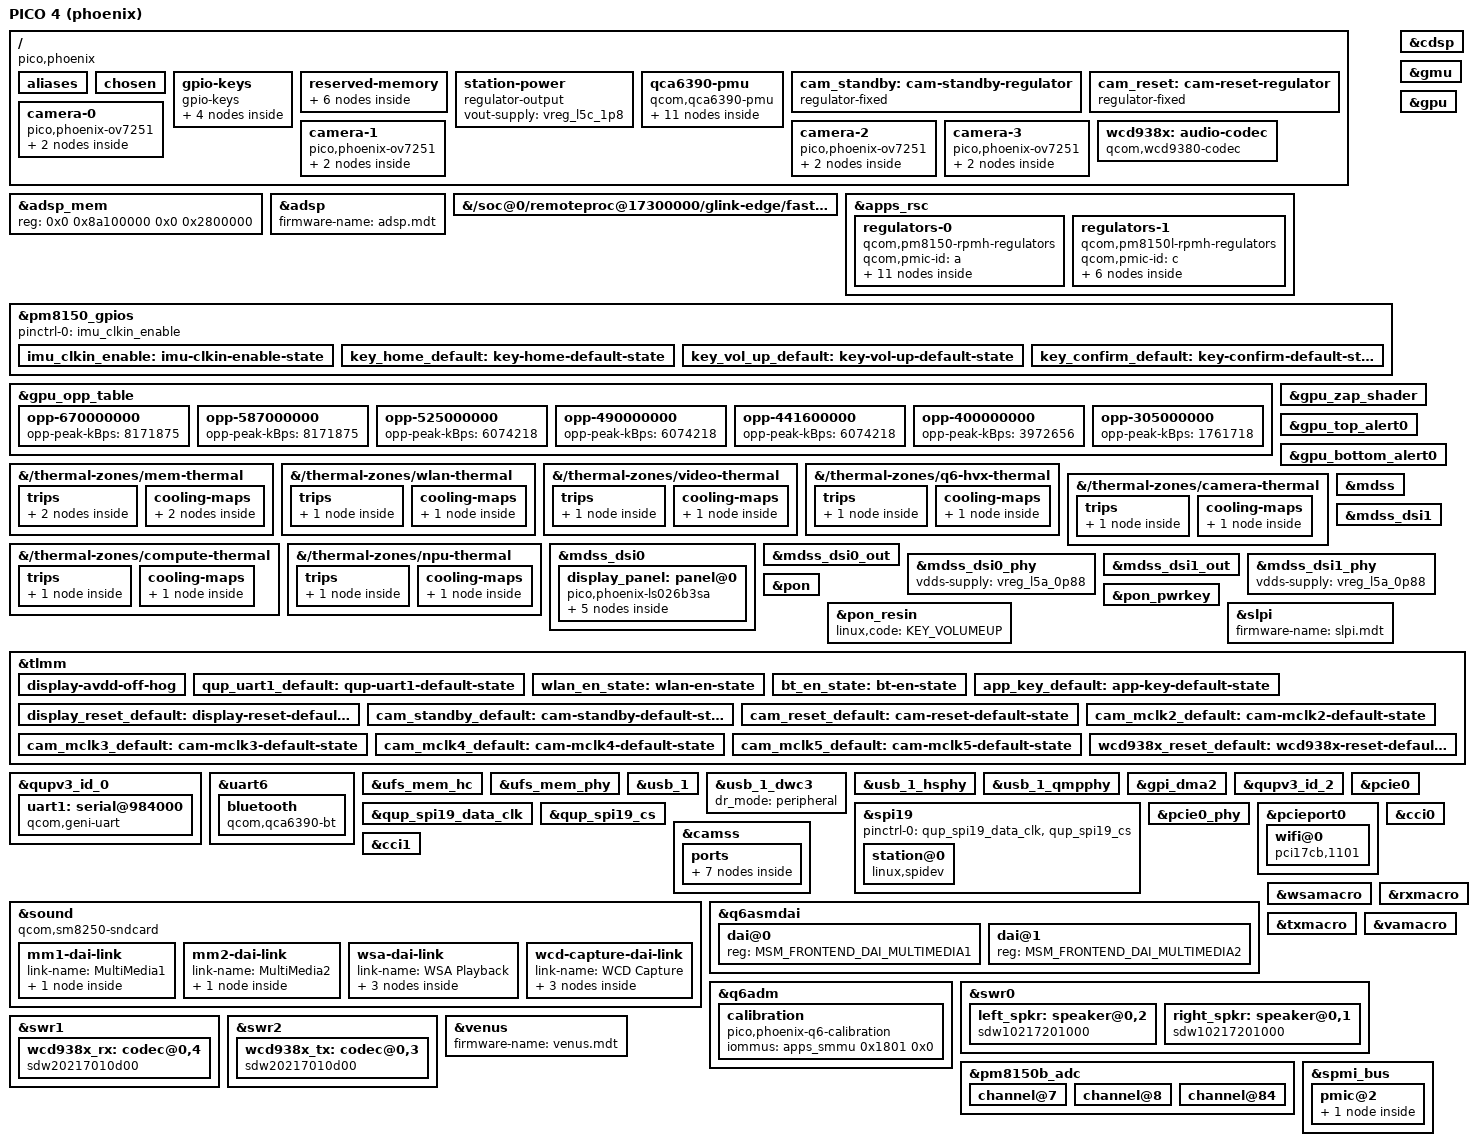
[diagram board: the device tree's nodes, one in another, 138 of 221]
// SPDX-License-Identifier: BSD-3-Clause
/*
 * PICO 4 (phoenix) on a mainline-based kernel: the prototype of a Steam Frame-level kernel
 * (docs/kernel-feasibility.md). Phase 0: storage, the USB gadget, reboot modes and a RAM
 * console. Phase 1: the two panels on the bonded DSI links, and the GPU.
 *
 * The board is Qualcomm's "kona MTP" design (the stock tree is kona v2.1 with the MTP overlay,
 * board-id 0x10008). Supplies, memory carve-outs and GPIOs follow the headset's own stock tree,
 * read from the running stock kernel, not mainline's MTP where the two differ.
 */

/dts-v1/;

#include <dt-bindings/arm/qcom,ids.h>
#include <dt-bindings/firmware/qcom,scm.h>
#include <dt-bindings/input/input.h>
#include <dt-bindings/regulator/qcom,rpmh-regulator.h>
#include "sm8250.dtsi"
#include "pm8150.dtsi"
/* PM8150B: the charger and fuel gauge's PMIC (its temperature alarm, ADC and GPIOs here). */
#include "pm8150b.dtsi"

/ {
	model = "PICO 4 (phoenix)";
	compatible = "pico,phoenix", "qcom,sm8250";
	chassis-type = "embedded";

	/*
	 * The ABL's board overlay replaces the root's compatible and model with downstream ones
	 * ("qcom,kona-mtp"); the kernel puts these back (patches/0003), so that drivers matching
	 * on the machine find "qcom,sm8250".
	 */
	pico4,compatible = "pico,phoenix", "qcom,sm8250";
	pico4,model = "PICO 4 (phoenix)";

	/*
	 * The ABL picks the base tree by SoC (SM8250 v2.1); the stock base trees carry board-id 0,
	 * the board comes from the dtbo overlay.
	 */
	qcom,msm-id = <QCOM_ID_SM8250 0x20001>;
	qcom,board-id = <0 0>;

	/* The GD32 MCU's UART keeps its stock name, which the fan, IPD and lens tools open. */
	aliases {
		serial1 = &uart1;
		/* The station's bus as bus 0: its spidev is /dev/spidev0.0, as on the stock kernel. */
		spi0 = &spi19;
	};

	chosen {
		#address-cells = <2>;
		#size-cells = <2>;
		ranges;
	};

	/*
	 * The stock tree's GPIO keys, with its labels and codes (its "volume_up" sends
	 * KEY_VOLUMEDOWN, as on PICO OS).
	 */
	gpio-keys {
		compatible = "gpio-keys";
		label = "gpio-keys";
		pinctrl-names = "default";
		pinctrl-0 = <&key_vol_up_default>, <&key_home_default>, <&key_confirm_default>,
			    <&app_key_default>;

		key-volume-up {
			label = "volume_up";
			gpios = <&pm8150_gpios 6 GPIO_ACTIVE_LOW>;
			linux,input-type = <EV_KEY>;
			linux,code = <KEY_VOLUMEDOWN>;
			wakeup-source;
			debounce-interval = <15>;
			linux,can-disable;
		};

		key-confirm {
			label = "confirm_key";
			gpios = <&pm8150_gpios 7 GPIO_ACTIVE_LOW>;
			linux,input-type = <EV_KEY>;
			linux,code = <KEY_ENTER>;
			wakeup-source;
			debounce-interval = <15>;
			linux,can-disable;
		};

		key-home {
			label = "home";
			gpios = <&pm8150_gpios 1 GPIO_ACTIVE_LOW>;
			linux,input-type = <EV_KEY>;
			linux,code = <KEY_HOME>;
			wakeup-source;
			debounce-interval = <15>;
			linux,can-disable;
		};

		key-app {
			label = "app_key";
			gpios = <&tlmm 40 GPIO_ACTIVE_LOW>;
			linux,input-type = <EV_KEY>;
			linux,code = <KEY_BACK>;
			wakeup-source;
			debounce-interval = <15>;
			linux,can-disable;
		};
	};

	reserved-memory {
		/*
		 * A RAM console that survives a warm reboot, laid out exactly as the stock kernel's
		 * (ramoops_memreserve=2M: 1 MiB console, 1 MiB pmsg, no dump records, no ECC), so
		 * that what a failed boot printed is in /sys/fs/pstore of the installed system on
		 * the stock kernel. Directly above the ABL's ramdisk and device tree.
		 */
		ramoops@b0000000 {
			compatible = "ramoops";
			reg = <0x0 0xb0000000 0x0 0x200000>;
			console-size = <0x100000>;
			pmsg-size = <0x100000>;
			record-size = <0>;
			no-map;
		};

		/* The stock tree's spss region (mainline's sits inside the stock adsp region). */
		spss_region: memory@8c900000 {
			reg = <0x0 0x8c900000 0x0 0x100000>;
			no-map;
		};

		/* Kept reserved like mainline's cdsp_secure_heap, moved behind the stock spss region. */
		cdsp_secure_region: memory@8ca00000 {
			reg = <0x0 0x8ca00000 0x0 0x4600000>;
			no-map;
		};

		/* The ABL's boot splash, still scanned out when the kernel starts. */
		cont_splash_region: memory@9c000000 {
			reg = <0x0 0x9c000000 0x0 0x3400000>;
			no-map;
		};

		dfps_data_region: memory@9f400000 {
			reg = <0x0 0x9f400000 0x0 0x40000>;
			no-map;
		};

		/*
		 * The stock remote heap for the audio DSP's static process (its adsp_region: 12 MiB
		 * of CMA below 4 GiB, 4 MiB aligned), which FastRPC hands to the DSP.
		 */
		adsp_rpc_heap: adsp-rpc-heap {
			compatible = "shared-dma-pool";
			alloc-ranges = <0x0 0x0 0x0 0xffffffff>;
			reusable;
			alignment = <0x0 0x400000>;
			size = <0x0 0xc00000>;
		};
	};
};

/delete-node/ &spss_mem;
/delete-node/ &cdsp_secure_heap;

/* The stock tree's adsp carve-out is 40 MiB (mainline: 29 MiB). */
&adsp_mem {
	reg = <0x0 0x8a100000 0x0 0x2800000>;
};

/*
 * The three DSPs with PICO's own signed images from the headset's modem partition, which the
 * userspace installs in /usr/lib/firmware: the audio DSP, the sensor DSP (head IMU, controllers
 * through ble_mcu, proximity) and the compute DSP (PICO OS's tracker). Their carve-outs are the
 * stock tree's. Without the files at probe (stage 1), each stays offline until it is started.
 */
&adsp {
	firmware-name = "adsp.mdt";
	status = "okay";
};

/*
 * The audio DSP's FastRPC channel: PICO OS's audio process (audiopd, which the userspace starts)
 * gets the stock remote heap, given to the DSP's VMs as the stock tree gives it
 * (qcom,adsp-remoteheap-vmid).
 */
&{/soc@0/remoteproc@17300000/glink-edge/fastrpc} {
	memory-region = <&adsp_rpc_heap>;
	qcom,vmids = <QCOM_SCM_VMID_LPASS QCOM_SCM_VMID_ADSP_HEAP>;
};

&apps_rsc {
	regulators-0 {
		compatible = "qcom,pm8150-rpmh-regulators";
		qcom,pmic-id = "a";

		/* Only the supplies the enabled blocks use; the voltages are the stock tree's. */
		vreg_s4a_1p8: smps4 {
			regulator-name = "vreg_s4a_1p8";
			regulator-min-microvolt = <1800000>;
			regulator-max-microvolt = <1920000>;
		};

		/*
		 * The QCA6390's 1.9 V and 0.95 V rails. The stock WLAN and Bluetooth drivers ask RPMh
		 * for 1.9 V and 0.95 V, which mainline can only vote in the regulators' steps: the next
		 * ones up, as RPMh rounds.
		 */
		vreg_s5a_1p9: smps5 {
			regulator-name = "vreg_s5a_1p9";
			regulator-min-microvolt = <1904000>;
			regulator-max-microvolt = <1904000>;
			regulator-initial-mode = <RPMH_REGULATOR_MODE_HPM>;
		};

		vreg_s6a_0p95: smps6 {
			regulator-name = "vreg_s6a_0p95";
			regulator-min-microvolt = <952000>;
			regulator-max-microvolt = <952000>;
			regulator-initial-mode = <RPMH_REGULATOR_MODE_HPM>;
		};

		vreg_l2a_3p1: ldo2 {
			regulator-name = "vreg_l2a_3p1";
			regulator-min-microvolt = <3072000>;
			regulator-max-microvolt = <3072000>;
			regulator-initial-mode = <RPMH_REGULATOR_MODE_HPM>;
		};

		vreg_l5a_0p88: ldo5 {
			regulator-name = "vreg_l5a_0p88";
			regulator-min-microvolt = <880000>;
			regulator-max-microvolt = <880000>;
			regulator-initial-mode = <RPMH_REGULATOR_MODE_HPM>;
		};

		vreg_l6a_1p2: ldo6 {
			regulator-name = "vreg_l6a_1p2";
			regulator-min-microvolt = <1200000>;
			regulator-max-microvolt = <1200000>;
			regulator-initial-mode = <RPMH_REGULATOR_MODE_HPM>;
		};

		/*
		 * The panels' VDDIO: the stock tree allows 1.8-1.9 V and its panel driver asks RPMh
		 * for 1.9 V. Mainline needs an exact LDO step (8 mV from 1.504 V): 1.896 V is the
		 * closest within the stock range. Enabling it at 1.904 V, above the range, stalled
		 * CPU 0.
		 */
		vreg_l7a_1p9: ldo7 {
			regulator-name = "vreg_l7a_1p9";
			regulator-min-microvolt = <1896000>;
			regulator-max-microvolt = <1896000>;
			regulator-initial-mode = <RPMH_REGULATOR_MODE_HPM>;
		};

		vreg_l9a_1p2: ldo9 {
			regulator-name = "vreg_l9a_1p2";
			regulator-min-microvolt = <1200000>;
			regulator-max-microvolt = <1200000>;
			regulator-initial-mode = <RPMH_REGULATOR_MODE_HPM>;
		};

		vreg_l12a_1p8: ldo12 {
			regulator-name = "vreg_l12a_1p8";
			regulator-min-microvolt = <1800000>;
			regulator-max-microvolt = <1800000>;
			regulator-initial-mode = <RPMH_REGULATOR_MODE_HPM>;
		};

		/* UFS 3.1 VCC: the stock driver asks for 2.504-2.95 V. */
		vreg_l17a_2p5: ldo17 {
			regulator-name = "vreg_l17a_2p5";
			regulator-min-microvolt = <2504000>;
			regulator-max-microvolt = <2952000>;
			regulator-initial-mode = <RPMH_REGULATOR_MODE_HPM>;
		};

		vreg_l18a_0p9: ldo18 {
			regulator-name = "vreg_l18a_0p9";
			regulator-min-microvolt = <912000>;
			regulator-max-microvolt = <920000>;
			regulator-initial-mode = <RPMH_REGULATOR_MODE_HPM>;
		};
	};

	regulators-1 {
		compatible = "qcom,pm8150l-rpmh-regulators";
		qcom,pmic-id = "c";

		/*
		 * The GD32 MCU's supply at the stock initial 3.0 V: the stock tree gives it to the
		 * MCU's UART, which keeps it on. The MCU drives the backlight, the fan and the
		 * lens motor, so it stays on here too.
		 */
		vreg_l10c_3p0: ldo10 {
			regulator-name = "vreg_l10c_3p0";
			regulator-min-microvolt = <3000000>;
			regulator-max-microvolt = <3000000>;
			regulator-initial-mode = <RPMH_REGULATOR_MODE_HPM>;
			regulator-always-on;
		};

		/*
		 * The head IMU's (TDK ICM-4x6xx on the sensor DSP) VDDIO and VDD at the stock voltages:
		 * the stock kernel's XR driver (qcom,xr-stdalonevwr-misc) holds both on.
		 */
		vreg_l8c_1p8: ldo8 {
			regulator-name = "vreg_l8c_1p8";
			regulator-min-microvolt = <1800000>;
			regulator-max-microvolt = <1800000>;
			regulator-initial-mode = <RPMH_REGULATOR_MODE_HPM>;
			regulator-always-on;
		};

		/* The QCA6390's 1.35 V rail (the stock drivers' 1.35 V, the next step up). */
		vreg_s8c_1p3: smps8 {
			regulator-name = "vreg_s8c_1p3";
			regulator-min-microvolt = <1352000>;
			regulator-max-microvolt = <1352000>;
			regulator-initial-mode = <RPMH_REGULATOR_MODE_HPM>;
		};

		vreg_l11c_3p0: ldo11 {
			regulator-name = "vreg_l11c_3p0";
			regulator-min-microvolt = <3008000>;
			regulator-max-microvolt = <3008000>;
			regulator-initial-mode = <RPMH_REGULATOR_MODE_HPM>;
			regulator-always-on;
		};

		/*
		 * PM8150L's BOB at the stock range: the stock tree's supply for the codec's
		 * microphone bias and a supply every camera sensor node names (cam_bob-supply).
		 */
		vreg_bob: bob {
			regulator-name = "vreg_bob";
			regulator-min-microvolt = <3008000>;
			regulator-max-microvolt = <3960000>;
			regulator-initial-mode = <RPMH_REGULATOR_MODE_AUTO>;
		};

		/*
		 * The controller station's supply at the stock initial 1.8 V: the stock tree gives it
		 * to the station's SPI bus (vdd-supply), whose vendor spidev switches it with a power
		 * ioctl. Here station-power hands that switch to userspace. On at boot: RPMh reports
		 * a regulator's state only once it has been set, and the switch needs to know it.
		 */
		vreg_l5c_1p8: ldo5 {
			regulator-name = "vreg_l5c_1p8";
			regulator-min-microvolt = <1800000>;
			regulator-max-microvolt = <1800000>;
			regulator-initial-mode = <RPMH_REGULATOR_MODE_HPM>;
			regulator-boot-on;
		};
	};
};

/*
 * The head IMU's CLKIN: PM8150's GPIO 3 in its first special function, the clock the IMU runs
 * from, as the stock XR driver sets it ("imu_clkin_enable").
 */
&pm8150_gpios {
	pinctrl-names = "default";
	pinctrl-0 = <&imu_clkin_enable>;

	imu_clkin_enable: imu-clkin-enable-state {
		pins = "gpio3";
		function = "func1";
		power-source = <0>;
		output-low;
		bias-disable;
		input-disable;
	};

	/* The keys' pins as the stock tree configures them. */
	key_home_default: key-home-default-state {
		pins = "gpio1";
		function = "normal";
		input-enable;
		bias-pull-up;
		power-source = <0>;
	};

	key_vol_up_default: key-vol-up-default-state {
		pins = "gpio6";
		function = "normal";
		input-enable;
		bias-pull-up;
		power-source = <1>;
	};

	key_confirm_default: key-confirm-default-state {
		pins = "gpio7";
		function = "normal";
		input-enable;
		bias-pull-up;
		power-source = <1>;
	};
};

/*
 * The stock loader holds a bus vote from the compute DSP to its memory NoC while it starts
 * (master 154 to slave 10070, the path mainline names qnm_npu to qns_cdsp_mem_noc); without
 * it, TrustZone refuses the start ("failed to authenticate image and release reset").
 */
&cdsp {
	firmware-name = "cdsp.mdt";
	interconnects = <&compute_noc MASTER_NPU 0 &compute_noc SLAVE_CDSP_MEM_NOC 0>;
	status = "okay";
};

&gmu {
	status = "okay";
};

/*
 * The GPU's own DDR vote, as the stock driver casts it: mainline's tree gives the A650 no
 * interconnect, so the DDR ran at what the CPUs asked for and the GPU's frames took up to a third
 * longer whenever they asked little. The stock tree's GPU bus table for LPDDR4X (the bootloader's
 * ddr_device_type 7) at each level's bus-freq-ddr7; KGSL's bus scaling between the levels'
 * bus-min and bus-max is not carried over: measured on the USB input with the battery full, the
 * stock levels' bus-min votes drew the same as these (within 1 %, the windows' spread 4 %), and the
 * top level's minimum is its vote. msm applies the OPP, and with it this vote, on every frequency
 * change.
 */
&gpu {
	interconnects = <&gem_noc MASTER_GRAPHICS_3D 0 &mc_virt SLAVE_EBI_CH0 0>;
	interconnect-names = "gfx-mem";
	status = "okay";
};

&gpu_opp_table {
	/*
	 * Not this headset's speed bin, but the OPP core looks for bandwidths in the first OPP only
	 * and without one there takes the table for one without them; the stock top level.
	 */
	opp-670000000 {
		opp-peak-kBps = <8171875>;	/* bus level 11 */
	};

	opp-587000000 {
		opp-peak-kBps = <8171875>;	/* bus level 11 */
	};

	opp-525000000 {
		opp-peak-kBps = <6074218>;	/* bus level 9 */
	};

	opp-490000000 {
		opp-peak-kBps = <6074218>;	/* bus level 9 */
	};

	opp-441600000 {
		opp-peak-kBps = <6074218>;	/* bus level 9 */
	};

	opp-400000000 {
		opp-peak-kBps = <3972656>;	/* bus level 7 */
	};

	opp-305000000 {
		opp-peak-kBps = <1761718>;	/* bus level 3 */
	};
};

/* PICO's signed zap shader, from the stock firmware (split .mdt with its segments). */
&gpu_zap_shader {
	firmware-name = "qcom/sm8250/pico/phoenix/a650_zap.mdt";
};

/*
 * The stock tree's kernel throttling, on mainline's zones: the GPU from 95 °C (gpuss-max-step;
 * mainline throttles at 85 °C, which a VR session reaches), the big and prime cores from a DDR
 * at 95 °C (pop-mem-step), and the GPU held at its second-lowest level, 400 MHz, from 100 °C at
 * the WLAN, video, DDR, DSP, camera, compute and NPU sensors (their -step zones; the stock tree
 * also caps the CDSP, the modem and the NPU there, which have no cooling devices here). The
 * CPUs keep mainline's frequency trips at 90 and 95 °C: the stock kernel only isolates cores at
 * 110 °C and leaves the rest to the CPUs' limits hardware, and 90 °C is this project's limit.
 */
&gpu_top_alert0 {
	temperature = <95000>;
	hysteresis = <0>;
};

&gpu_bottom_alert0 {
	temperature = <95000>;
	hysteresis = <0>;
};

&{/thermal-zones/mem-thermal} {
	trips {
		mem_pop: trip-pop {
			temperature = <95000>;
			hysteresis = <0>;
			type = "passive";
		};

		mem_step: trip-step {
			temperature = <100000>;
			hysteresis = <5000>;
			type = "passive";
		};
	};

	cooling-maps {
		map-pop {
			trip = <&mem_pop>;
			cooling-device = <&cpu4 THERMAL_NO_LIMIT THERMAL_NO_LIMIT>,
					 <&cpu7 THERMAL_NO_LIMIT THERMAL_NO_LIMIT>;
		};

		map-step {
			trip = <&mem_step>;
			cooling-device = <&gpu 4 4>;
		};
	};
};

&{/thermal-zones/wlan-thermal} {
	trips {
		wlan_step: trip-step {
			temperature = <100000>;
			hysteresis = <5000>;
			type = "passive";
		};
	};

	cooling-maps {
		map-step {
			trip = <&wlan_step>;
			cooling-device = <&gpu 4 4>;
		};
	};
};

&{/thermal-zones/video-thermal} {
	trips {
		video_step: trip-step {
			temperature = <100000>;
			hysteresis = <5000>;
			type = "passive";
		};
	};

	cooling-maps {
		map-step {
			trip = <&video_step>;
			cooling-device = <&gpu 4 4>;
		};
	};
};

&{/thermal-zones/q6-hvx-thermal} {
	trips {
		q6_hvx_step: trip-step {
			temperature = <100000>;
			hysteresis = <5000>;
			type = "passive";
		};
	};

	cooling-maps {
		map-step {
			trip = <&q6_hvx_step>;
			cooling-device = <&gpu 4 4>;
		};
	};
};

&{/thermal-zones/camera-thermal} {
	trips {
		camera_step: trip-step {
			temperature = <100000>;
			hysteresis = <5000>;
			type = "passive";
		};
	};

	cooling-maps {
		map-step {
			trip = <&camera_step>;
			cooling-device = <&gpu 4 4>;
		};
	};
};

&{/thermal-zones/compute-thermal} {
	trips {
		compute_step: trip-step {
			temperature = <100000>;
			hysteresis = <5000>;
			type = "passive";
		};
	};

	cooling-maps {
		map-step {
			trip = <&compute_step>;
			cooling-device = <&gpu 4 4>;
		};
	};
};

&{/thermal-zones/npu-thermal} {
	trips {
		npu_step: trip-step {
			temperature = <100000>;
			hysteresis = <5000>;
			type = "passive";
		};
	};

	cooling-maps {
		map-step {
			trip = <&npu_step>;
			cooling-device = <&gpu 4 4>;
		};
	};
};

&mdss {
	status = "okay";
};

/*
 * Two Sharp LS026B3SA panels, one per DSI link, as one bonded output: the first link is the
 * master, and both run from its PLL (the stock display's dsi-ctrl-num <0 1>).
 */
&mdss_dsi0 {
	vdda-supply = <&vreg_l9a_1p2>;
	qcom,dual-dsi-mode;
	qcom,master-dsi;
	status = "okay";

	display_panel: panel@0 {
		compatible = "pico,phoenix-ls026b3sa";
		reg = <0>;

		reset-gpios = <&tlmm 75 GPIO_ACTIVE_LOW>;
		vio-gpios = <&tlmm 133 GPIO_ACTIVE_HIGH>;
		backlight-gpios = <&tlmm 29 GPIO_ACTIVE_HIGH>;
		pinctrl-0 = <&display_reset_default>;
		pinctrl-names = "default";

		vddio-supply = <&vreg_l7a_1p9>;

		ports {
			#address-cells = <1>;
			#size-cells = <0>;

			port@0 {
				reg = <0>;
				panel_in0: endpoint {
					remote-endpoint = <&mdss_dsi0_out>;
				};
			};

			port@1 {
				reg = <1>;
				panel_in1: endpoint {
					remote-endpoint = <&mdss_dsi1_out>;
				};
			};
		};
	};
};

&mdss_dsi0_out {
	remote-endpoint = <&panel_in0>;
	data-lanes = <0 1 2 3>;
};

&mdss_dsi0_phy {
	vdds-supply = <&vreg_l5a_0p88>;
	status = "okay";
};

&mdss_dsi1 {
	vdda-supply = <&vreg_l9a_1p2>;
	qcom,dual-dsi-mode;
	assigned-clocks = <&dispcc DISP_CC_MDSS_BYTE1_CLK_SRC>, <&dispcc DISP_CC_MDSS_PCLK1_CLK_SRC>;
	assigned-clock-parents = <&mdss_dsi0_phy DSI_BYTE_PLL_CLK>, <&mdss_dsi0_phy DSI_PIXEL_PLL_CLK>;
	status = "okay";
};

&mdss_dsi1_out {
	remote-endpoint = <&panel_in1>;
	data-lanes = <0 1 2 3>;
};

&mdss_dsi1_phy {
	vdds-supply = <&vreg_l5a_0p88>;
	status = "okay";
};

&pon {
	mode-bootloader = <0x2>;
	mode-recovery = <0x1>;
};

/* The stock tree's power-on keys: KPDPWR is the power key, RESIN sends KEY_VOLUMEUP. */
&pon_pwrkey {
	status = "okay";
};

&pon_resin {
	linux,code = <KEY_VOLUMEUP>;
	status = "okay";
};

&slpi {
	firmware-name = "slpi.mdt";
	status = "okay";
};

&tlmm {
	/*
	 * Every GPIO the stock tree leaves unused (no pin configuration, no consumer) stays
	 * untouched, which covers the secure ones whose registers fault when read.
	 */
	gpio-reserved-ranges = <14 1>, <24 2>, <27 2>, <30 2>, <64 1>, <66 1>, <73 1>,
			       <88 3>, <112 2>, <120 5>, <146 34>;

	/*
	 * GPIO 71 switches a 5.5 V supply that the bootloader leaves on. The stock display does
	 * not use it, and the stock kernel switches it off as unused.
	 */
	display-avdd-off-hog {
		gpio-hog;
		gpios = <71 GPIO_ACTIVE_HIGH>;
		output-low;
		line-name = "display-avdd-off";
	};

	/* The GD32 MCU's UART, two wires as in the stock tree (its reset and boot lines stay unused). */
	qup_uart1_default: qup-uart1-default-state {
		pins = "gpio6", "gpio7";
		function = "qup1";
		drive-strength = <2>;
		bias-disable;
	};

	/* The QCA6390's enable lines as the stock tree configures them (cnss2's active state, btpower's). */
	wlan_en_state: wlan-en-state {
		pins = "gpio20";
		function = "gpio";
		drive-strength = <16>;
		bias-pull-up;
	};

	bt_en_state: bt-en-state {
		pins = "gpio21";
		function = "gpio";
		drive-strength = <2>;
		bias-pull-down;
	};

	/* The app key's pin as the stock tree configures it. */
	app_key_default: app-key-default-state {
		pins = "gpio40";
		function = "gpio";
		drive-strength = <6>;
		bias-pull-up;
	};

	/* The stock panel pins: the reset (75) and its neighbour 60, driven at 8 mA. */
	display_reset_default: display-reset-default-state {
		pins = "gpio75", "gpio60";
		function = "gpio";
		drive-strength = <8>;
		bias-disable;
	};
};

&qupv3_id_0 {
	status = "okay";

	/* QUP0's serial engine 1 as the stock tree uses it: the GD32 MCU at 115200 baud. */
	uart1: serial@984000 {
		compatible = "qcom,geni-uart";
		reg = <0 0x00984000 0 0x4000>;
		clock-names = "se";
		clocks = <&gcc GCC_QUPV3_WRAP0_S1_CLK>;
		pinctrl-names = "default";
		pinctrl-0 = <&qup_uart1_default>;
		interrupts = <GIC_SPI 602 IRQ_TYPE_LEVEL_HIGH>;
		power-domains = <&rpmhpd RPMHPD_CX>;
		operating-points-v2 = <&qup_opp_table>;
		interconnects = <&qup_virt MASTER_QUP_CORE_0 0 &qup_virt SLAVE_QUP_CORE_0 0>,
				<&gem_noc MASTER_AMPSS_M0 0 &config_noc SLAVE_QUP_0 0>;
		interconnect-names = "qup-core",
				     "qup-config";
	};
};

/*
 * Bluetooth: the QCA6390 on QUP0's serial engine 6, four wires, as the stock tree's
 * bt_qca6390 uses it.
 */
&uart6 {
	status = "okay";

	bluetooth {
		compatible = "qcom,qca6390-bt";

		vddrfacmn-supply = <&vreg_pmu_rfa_cmn>;
		vddaon-supply = <&vreg_pmu_aon_0p59>;
		vddbtcmx-supply = <&vreg_pmu_btcmx_0p85>;
		vddrfa0p8-supply = <&vreg_pmu_rfa_0p8>;
		vddrfa1p2-supply = <&vreg_pmu_rfa_1p2>;
		vddrfa1p7-supply = <&vreg_pmu_rfa_1p7>;
	};
};

&ufs_mem_hc {
	status = "okay";

	vcc-supply = <&vreg_l17a_2p5>;
	vcc-max-microamp = <800000>;
	vccq-supply = <&vreg_l6a_1p2>;
	vccq-max-microamp = <800000>;
	vccq2-supply = <&vreg_s4a_1p8>;
	vccq2-max-microamp = <800000>;
};

&ufs_mem_phy {
	status = "okay";

	vdda-phy-supply = <&vreg_l5a_0p88>;
	vdda-pll-supply = <&vreg_l9a_1p2>;
};

&usb_1 {
	status = "okay";
};

/* Device mode only: the headset is the PC's network adapter, as in stage 1 on the stock kernel. */
&usb_1_dwc3 {
	dr_mode = "peripheral";
};

&usb_1_hsphy {
	status = "okay";

	vdda-pll-supply = <&vreg_l5a_0p88>;
	vdda18-supply = <&vreg_l12a_1p8>;
	vdda33-supply = <&vreg_l2a_3p1>;
};

&usb_1_qmpphy {
	status = "okay";

	vdda-phy-supply = <&vreg_l9a_1p2>;
	vdda-pll-supply = <&vreg_l18a_0p9>;
};

/*
 * The controller station (Nordic nRF52832) on QUP2's serial engine 5 (SE19), as the stock board
 * overlay describes it: "picovr,nordic" at up to 6 MHz on GPIO 0-3 (6 mA), its interrupt line on
 * GPIO 11 (rfic-io2 and rfic-io3 on GPIO 4 and 8), and the camera frame sync on GPIO 84
 * (stationdev). Here it is a spidev, and userspace reads GPIO 11. Its power, L5C, is the
 * station-power output's state in sysfs, which takes the place of the vendor spidev's power
 * ioctl. The station's boot pin, GPIO 10, stays untouched: it selects the station's bootloader.
 */
&gpi_dma2 {
	status = "okay";
};

&qupv3_id_2 {
	status = "okay";
};

&qup_spi19_data_clk {
	drive-strength = <6>;
	bias-disable;
};

&qup_spi19_cs {
	drive-strength = <6>;
	bias-disable;
};

&spi19 {
	pinctrl-names = "default";
	pinctrl-0 = <&qup_spi19_data_clk>, <&qup_spi19_cs>;
	status = "okay";

	station@0 {
		compatible = "linux,spidev";
		reg = <0>;
		spi-max-frequency = <6000000>;
	};
};

/ {
	station-power {
		compatible = "regulator-output";
		vout-supply = <&vreg_l5c_1p8>;
	};
};

/*
 * Wi-Fi and Bluetooth: the QCA6390, wired as on Qualcomm's SM8250 reference boards. Its
 * power-management unit takes the stock tree's supplies (cnss2's vdd-wlan-* and btpower's
 * qca,bt-vdd-*: S6A for the 0.95 V rails, S8C for 1.35 V, S5A for 1.9 V, S4A for the I/O) and
 * enable lines (WLAN GPIO 20, Bluetooth GPIO 21); the WLAN function sits on PCIe 0 (the stock
 * tree's cnss_pci on pcie0_rp, the same reset, clock request and wake pins as mainline's).
 * The stock Bluetooth driver's antenna-sharing supply (L16A) and switch control (GPIO 124)
 * have no place in the mainline binding.
 */
/ {
	qca6390-pmu {
		compatible = "qcom,qca6390-pmu";

		pinctrl-names = "default";
		pinctrl-0 = <&bt_en_state>, <&wlan_en_state>;

		vddaon-supply = <&vreg_s6a_0p95>;
		vddpmu-supply = <&vreg_s6a_0p95>;
		vddrfa0p95-supply = <&vreg_s6a_0p95>;
		vddrfa1p3-supply = <&vreg_s8c_1p3>;
		vddrfa1p9-supply = <&vreg_s5a_1p9>;
		vddpcie1p3-supply = <&vreg_s8c_1p3>;
		vddpcie1p9-supply = <&vreg_s5a_1p9>;
		vddio-supply = <&vreg_s4a_1p8>;

		wlan-enable-gpios = <&tlmm 20 GPIO_ACTIVE_HIGH>;
		bt-enable-gpios = <&tlmm 21 GPIO_ACTIVE_HIGH>;

		regulators {
			vreg_pmu_rfa_cmn: ldo0 {
				regulator-name = "vreg_pmu_rfa_cmn";
			};

			vreg_pmu_aon_0p59: ldo1 {
				regulator-name = "vreg_pmu_aon_0p59";
			};

			vreg_pmu_wlcx_0p8: ldo2 {
				regulator-name = "vreg_pmu_wlcx_0p8";
			};

			vreg_pmu_wlmx_0p85: ldo3 {
				regulator-name = "vreg_pmu_wlmx_0p85";
			};

			vreg_pmu_btcmx_0p85: ldo4 {
				regulator-name = "vreg_pmu_btcmx_0p85";
			};

			vreg_pmu_rfa_0p8: ldo5 {
				regulator-name = "vreg_pmu_rfa_0p8";
			};

			vreg_pmu_rfa_1p2: ldo6 {
				regulator-name = "vreg_pmu_rfa_1p2";
			};

			vreg_pmu_rfa_1p7: ldo7 {
				regulator-name = "vreg_pmu_rfa_1p7";
			};

			vreg_pmu_pcie_0p9: ldo8 {
				regulator-name = "vreg_pmu_pcie_0p9";
			};

			vreg_pmu_pcie_1p8: ldo9 {
				regulator-name = "vreg_pmu_pcie_1p8";
			};
		};
	};
};

&pcie0 {
	status = "okay";
};

/* The stock tree's PCIe 0 PHY supplies, the UFS PHY's: L5A 0.88 V and L9A 1.2 V. */
&pcie0_phy {
	vdda-phy-supply = <&vreg_l5a_0p88>;
	vdda-pll-supply = <&vreg_l9a_1p2>;
	status = "okay";
};

&pcieport0 {
	wifi@0 {
		compatible = "pci17cb,1101";
		reg = <0x10000 0x0 0x0 0x0 0x0>;

		vddrfacmn-supply = <&vreg_pmu_rfa_cmn>;
		vddaon-supply = <&vreg_pmu_aon_0p59>;
		vddwlcx-supply = <&vreg_pmu_wlcx_0p8>;
		vddwlmx-supply = <&vreg_pmu_wlmx_0p85>;
		vddrfa0p8-supply = <&vreg_pmu_rfa_0p8>;
		vddrfa1p2-supply = <&vreg_pmu_rfa_1p2>;
		vddrfa1p7-supply = <&vreg_pmu_rfa_1p7>;
		vddpcie0p9-supply = <&vreg_pmu_pcie_0p9>;
		vddpcie1p8-supply = <&vreg_pmu_pcie_1p8>;
	};
};

/*
 * The four tracking cameras (OmniVision OV7251, 640x480 mono, one CSI-2 lane each), as the stock
 * board overlay wires them (its cam-sensor cells 0-3): MCLK 24 MHz from the camera clock
 * controller, one lane at 480 Mbit/s. Cells 1 and 2 share CSIPHY 3 in combo mode.
 * All four share their reset (GPIO 115) and standby (GPIO 42) lines; as fixed regulators the
 * two lines are switched once for all sensors. Power-up as the stock module's sequence: standby
 * and 18 ms, MCLK and 1 ms, reset and 18 ms.
 */
#include <dt-bindings/clock/qcom,camcc-sm8250.h>

/ {
	cam_standby: cam-standby-regulator {
		compatible = "regulator-fixed";
		regulator-name = "cam_standby";
		gpio = <&tlmm 42 GPIO_ACTIVE_HIGH>;
		enable-active-high;
		startup-delay-us = <18000>;
		pinctrl-names = "default";
		pinctrl-0 = <&cam_standby_default>;
	};

	cam_reset: cam-reset-regulator {
		compatible = "regulator-fixed";
		regulator-name = "cam_reset";
		gpio = <&tlmm 115 GPIO_ACTIVE_HIGH>;
		enable-active-high;
		startup-delay-us = <18000>;
		pinctrl-names = "default";
		pinctrl-0 = <&cam_reset_default>;
	};
};

&tlmm {
	cam_standby_default: cam-standby-default-state {
		pins = "gpio42";
		function = "gpio";
		drive-strength = <2>;
		bias-disable;
	};

	cam_reset_default: cam-reset-default-state {
		pins = "gpio115";
		function = "gpio";
		drive-strength = <2>;
		bias-disable;
	};

	/* The MCLK pins at 16 mA, as the stock camera stack drives them while the sensors run. */
	cam_mclk2_default: cam-mclk2-default-state {
		pins = "gpio96";
		function = "cam_mclk";
		drive-strength = <16>;
		bias-disable;
	};

	cam_mclk3_default: cam-mclk3-default-state {
		pins = "gpio97";
		function = "cam_mclk";
		drive-strength = <16>;
		bias-disable;
	};

	cam_mclk4_default: cam-mclk4-default-state {
		pins = "gpio98";
		function = "cam_mclk";
		drive-strength = <16>;
		bias-disable;
	};

	cam_mclk5_default: cam-mclk5-default-state {
		pins = "gpio99";
		function = "cam_mclk";
		drive-strength = <16>;
		bias-disable;
	};
};

&camss {
	vdda-phy-supply = <&vreg_l5a_0p88>;
	vdda-pll-supply = <&vreg_l9a_1p2>;
	status = "okay";

	ports {
		port@3 {
			#address-cells = <1>;
			#size-cells = <0>;

			csiphy3_cam1_ep: endpoint@0 {
				reg = <0>;
				clock-lanes = <7>;
				data-lanes = <0>;
				remote-endpoint = <&cam1_ep>;
			};

			/* The second sensor on the PHY (combo mode): data lane 2, lane 3 its clock. */
			csiphy3_cam2_ep: endpoint@1 {
				reg = <1>;
				clock-lanes = <3>;
				data-lanes = <2>;
				remote-endpoint = <&cam2_ep>;
			};
		};

		port@4 {
			csiphy4_ep: endpoint {
				clock-lanes = <7>;
				data-lanes = <0>;
				remote-endpoint = <&cam3_ep>;
			};
		};

		port@5 {
			csiphy5_ep: endpoint {
				clock-lanes = <7>;
				data-lanes = <0>;
				remote-endpoint = <&cam0_ep>;
			};
		};
	};
};

/* The CCIs run at the stock 37.5 MHz, the clock their I2C timings are made for (the default is 19.2). */
&cci0 {
	assigned-clocks = <&camcc CAM_CC_CCI_0_CLK_SRC>;
	assigned-clock-rates = <37500000>;
	status = "okay";
};

&cci1 {
	assigned-clocks = <&camcc CAM_CC_CCI_1_CLK_SRC>;
	assigned-clock-rates = <37500000>;
	status = "okay";
};

/*
 * The four tracking cameras (OV7251), each on its stock MCLK and CSIPHY. Their control port belongs
 * to the controller radio, which configures them and triggers each frame: PICO's stock kernel never
 * talks to them either (it takes their probes without reading a chip ID and drops their register
 * writes), so they are no I2C clients. Each holds the camera clock controller's TITAN_TOP GDSC, its
 * stock cam_clk supply, without which its MCLK does not run.
 */
/ {
	camera-0 {
		/* left, stock address 0xE2 */
		compatible = "pico,phoenix-ov7251";
		pico,camera-slot = <0>;
		clocks = <&camcc CAM_CC_MCLK3_CLK>;
		clock-names = "xclk";
		power-domains = <&camcc TITAN_TOP_GDSC>;
		assigned-clocks = <&camcc CAM_CC_MCLK3_CLK>;
		assigned-clock-rates = <24000000>;
		pinctrl-names = "default";
		pinctrl-0 = <&cam_mclk3_default>;
		standby-supply = <&cam_standby>;
		reset-supply = <&cam_reset>;

		port {
			cam0_ep: endpoint {
				data-lanes = <1>;
				link-frequencies = /bits/ 64 <240000000>;
				remote-endpoint = <&csiphy5_ep>;
			};
		};
	};

	camera-1 {
		/* right, 0xE4 */
		compatible = "pico,phoenix-ov7251";
		pico,camera-slot = <1>;
		clocks = <&camcc CAM_CC_MCLK4_CLK>;
		clock-names = "xclk";
		power-domains = <&camcc TITAN_TOP_GDSC>;
		assigned-clocks = <&camcc CAM_CC_MCLK4_CLK>;
		assigned-clock-rates = <24000000>;
		pinctrl-names = "default";
		pinctrl-0 = <&cam_mclk4_default>;
		standby-supply = <&cam_standby>;
		reset-supply = <&cam_reset>;

		port {
			cam1_ep: endpoint {
				data-lanes = <1>;
				link-frequencies = /bits/ 64 <240000000>;
				remote-endpoint = <&csiphy3_cam1_ep>;
			};
		};
	};

	camera-2 {
		/* "slave", 0xE6 */
		compatible = "pico,phoenix-ov7251";
		pico,camera-slot = <2>;
		clocks = <&camcc CAM_CC_MCLK2_CLK>;
		clock-names = "xclk";
		power-domains = <&camcc TITAN_TOP_GDSC>;
		assigned-clocks = <&camcc CAM_CC_MCLK2_CLK>;
		assigned-clock-rates = <24000000>;
		pinctrl-names = "default";
		pinctrl-0 = <&cam_mclk2_default>;
		standby-supply = <&cam_standby>;
		reset-supply = <&cam_reset>;

		port {
			cam2_ep: endpoint {
				data-lanes = <1>;
				link-frequencies = /bits/ 64 <240000000>;
				remote-endpoint = <&csiphy3_cam2_ep>;
			};
		};
	};

	camera-3 {
		/* "master", 0xE8 */
		compatible = "pico,phoenix-ov7251";
		pico,camera-slot = <3>;
		clocks = <&camcc CAM_CC_MCLK5_CLK>;
		clock-names = "xclk";
		power-domains = <&camcc TITAN_TOP_GDSC>;
		assigned-clocks = <&camcc CAM_CC_MCLK5_CLK>;
		assigned-clock-rates = <24000000>;
		pinctrl-names = "default";
		pinctrl-0 = <&cam_mclk5_default>;
		standby-supply = <&cam_standby>;
		reset-supply = <&cam_reset>;

		port {
			cam3_ep: endpoint {
				data-lanes = <1>;
				link-frequencies = /bits/ 64 <240000000>;
				remote-endpoint = <&csiphy4_ep>;
			};
		};
	};
};


/* Cells 0 (left, 0xE2) and 1 (right, 0xE4) on CCI 1, master 0, in fast mode as well. */
/*
 * Audio, as the stock tree wires it (kona-mtp-snd-card): two WSA8810 amplifiers, one per speaker,
 * on the WSA macro's SoundWire, and the WCD9380 codec (RX and TX SoundWire) whose ADC1 carries
 * the analog microphone (PICO OS's amic1, on MIC BIAS1). The DSP side is the audio DSP's APR
 * services (q6afe, q6asm, q6adm) in sm8250.dtsi.
 */
#include <dt-bindings/sound/qcom,q6afe.h>
#include <dt-bindings/sound/qcom,q6asm.h>

/ {
	wcd938x: audio-codec {
		compatible = "qcom,wcd9380-codec";

		pinctrl-names = "default";
		pinctrl-0 = <&wcd938x_reset_default>;
		reset-gpios = <&tlmm 32 GPIO_ACTIVE_LOW>;

		/* The stock supplies: S4A for the codec, BOB for the microphone bias. */
		vdd-buck-supply = <&vreg_s4a_1p8>;
		vdd-rxtx-supply = <&vreg_s4a_1p8>;
		vdd-io-supply = <&vreg_s4a_1p8>;
		vdd-mic-bias-supply = <&vreg_bob>;

		/* The stock 2.7 V on every bias. */
		qcom,micbias1-microvolt = <2700000>;
		qcom,micbias2-microvolt = <2700000>;
		qcom,micbias3-microvolt = <2700000>;
		qcom,micbias4-microvolt = <2700000>;
		/* The stock headphone switch (msm-mbhc-hphl-swh = 0); no jack is fitted. */
		qcom,hphl-jack-type-normally-closed;

		qcom,rx-device = <&wcd938x_rx>;
		qcom,tx-device = <&wcd938x_tx>;

		#sound-dai-cells = <1>;
	};
};

&sound {
	compatible = "qcom,sm8250-sndcard";
	model = "PICO4";
	audio-routing =
		"SpkrLeft IN", "WSA_SPK1 OUT",
		"SpkrRight IN", "WSA_SPK2 OUT",
		"AMIC1", "MIC BIAS1",
		"TX SWR_ADC0", "ADC1_OUTPUT";

	mm1-dai-link {
		link-name = "MultiMedia1";

		cpu {
			sound-dai = <&q6asmdai MSM_FRONTEND_DAI_MULTIMEDIA1>;
		};
	};

	mm2-dai-link {
		link-name = "MultiMedia2";

		cpu {
			sound-dai = <&q6asmdai MSM_FRONTEND_DAI_MULTIMEDIA2>;
		};
	};

	wsa-dai-link {
		link-name = "WSA Playback";

		cpu {
			sound-dai = <&q6afedai WSA_CODEC_DMA_RX_0>;
		};

		codec {
			sound-dai = <&left_spkr>, <&right_spkr>, <&swr0 0>, <&wsamacro 0>;
		};

		platform {
			sound-dai = <&q6routing>;
		};
	};

	wcd-capture-dai-link {
		link-name = "WCD Capture";

		cpu {
			sound-dai = <&q6afedai TX_CODEC_DMA_TX_3>;
		};

		codec {
			sound-dai = <&wcd938x 1>, <&swr2 0>, <&txmacro 0>;
		};

		platform {
			sound-dai = <&q6routing>;
		};
	};
};

/* The two front ends the card's links use: playback and capture. */
&q6asmdai {
	dai@0 {
		reg = <MSM_FRONTEND_DAI_MULTIMEDIA1>;
	};

	dai@1 {
		reg = <MSM_FRONTEND_DAI_MULTIMEDIA2>;
	};
};

/*
 * PICO OS's calibration (q6calibration-pico4.c, patch 0013): the custom topologies and each
 * path's ADM topology and parameters from its database. The ADSP reads the topologies through
 * the audio SMMU stream, as it reads the stream buffers.
 */
&q6adm {
	calibration {
		compatible = "pico,phoenix-q6-calibration";
		iommus = <&apps_smmu 0x1801 0x0>;
	};
};

&wsamacro {
	status = "okay";
};

&rxmacro {
	status = "okay";
};

&txmacro {
	status = "okay";
};

/* The stock VA macro's digital-microphone rate and bias supply. */
&vamacro {
	qcom,dmic-sample-rate = <600000>;
	vdd-micb-supply = <&vreg_s4a_1p8>;
};

/*
 * The speakers: WSA8810 units 1 (right, shutdown GPIO 127) and 2 (left, GPIO 129), the stock
 * 0x1020170211 and 0x1020170212.
 */
&swr0 {
	status = "okay";

	left_spkr: speaker@0,2 {
		compatible = "sdw10217201000";
		reg = <0 2>;
		powerdown-gpios = <&tlmm 129 GPIO_ACTIVE_LOW>;
		#thermal-sensor-cells = <0>;
		sound-name-prefix = "SpkrLeft";
		#sound-dai-cells = <0>;
	};

	right_spkr: speaker@0,1 {
		compatible = "sdw10217201000";
		reg = <0 1>;
		powerdown-gpios = <&tlmm 127 GPIO_ACTIVE_LOW>;
		#thermal-sensor-cells = <0>;
		sound-name-prefix = "SpkrRight";
		#sound-dai-cells = <0>;
	};
};

/* The codec's SoundWire units: RX 4 and TX 3 (the stock 0x...224 and 0x...223). */
&swr1 {
	status = "okay";

	wcd938x_rx: codec@0,4 {
		compatible = "sdw20217010d00";
		reg = <0 4>;
		qcom,rx-port-mapping = <1 2 3 4 5>;
	};
};

&swr2 {
	status = "okay";

	wcd938x_tx: codec@0,3 {
		compatible = "sdw20217010d00";
		reg = <0 3>;
		qcom,tx-port-mapping = <2 3 4 5>;
	};
};

&tlmm {
	wcd938x_reset_default: wcd938x-reset-default-state {
		pins = "gpio32";
		function = "gpio";
		drive-strength = <16>;
		output-high;
	};
};

/*
 * The video codec (Venus) with PICO's own firmware from the headset's modem partition, which the
 * userspace installs in /usr/lib/firmware; its carve-out is the stock tree's (video_mem).
 */
&venus {
	firmware-name = "venus.mdt";
	status = "okay";
};

/*
 * PM8150B's ADC also measures the USB input (its current as a sense voltage, its voltage divided by
 * 16) and the battery's voltage, as the stock tree's channels do: with the battery full, the USB
 * input carries what the headset draws.
 */
&pm8150b_adc {
	channel@7 {
		reg = <ADC5_USB_IN_I>;
		qcom,pre-scaling = <1 1>;
		label = "usb_in_i_uv";
	};

	channel@8 {
		reg = <ADC5_USB_IN_V_16>;
		qcom,pre-scaling = <1 16>;
		label = "usb_in_v_div_16";
	};

	channel@84 {
		reg = <ADC5_VBAT_SNS>;
		qcom,pre-scaling = <1 3>;
		label = "vbat_sns";
	};
};

/*
 * The battery: PM8150B's fuel gauge (its battery-SOC block) and charger with its USB input. They run
 * as PICO's boot loader set them up; the driver reports the level and the charger's state.
 */
&spmi_bus {
	pmic@2 {
		battery@4000 {
			compatible = "pico,phoenix-pm8150b-battery";
			reg = <0x4000>, <0x1000>, <0x1300>;
		};
	};
};

/*
 * The ABL lays the board overlay over this tree (from the dtbo partition, or the image's
 * recovery_dtbo). Its fragments target downstream labels; the build appends a node that
 * resolves every one of them to a node of its own, which no driver ever sees.
 */
#include "sm8250-pico4-phoenix-dtbo-sink.dtsi"

/* The panels' command sequences, which the build copies from the stock board overlay. */
#include "sm8250-pico4-phoenix-panel.dtsi"
